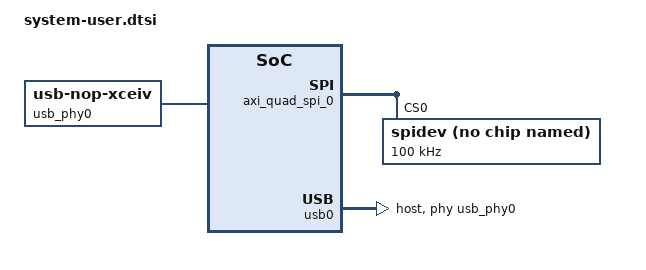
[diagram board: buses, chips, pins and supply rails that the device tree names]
/include/ "system-conf.dtsi"
/ {
	usb_phy0: usb_phy@0 {
		compatible = "usb-nop-xceiv";
		#phy-cells = <0>;
	};
};

&axi_quad_spi_0{
	spidev@0{
		compatible = "linux,spidev";
		spi-max-frequency = <100000>;
		reg = <0>;
	};
};

&usb0 {
 	dr_mode = "host";
 	usb-phy = <&usb_phy0>;
};

